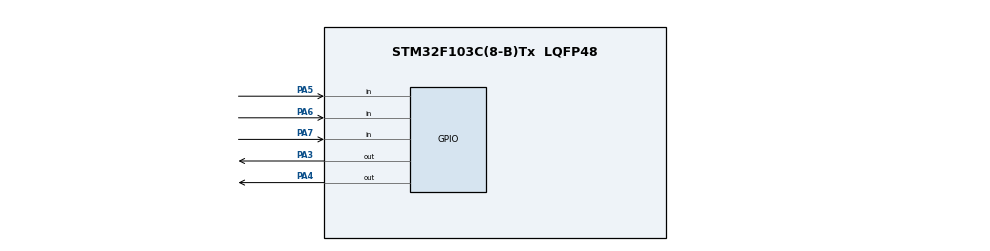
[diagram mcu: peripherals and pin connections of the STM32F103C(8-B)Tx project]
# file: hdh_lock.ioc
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FREERTOS.Tasks01=Task1,0,128,Task1_function,Default,NULL,Dynamic,NULL,NULL;Task2,0,128,Task2_function,Default,NULL,Dynamic,NULL,NULL;Task3,0,128,Task3_function,Default,NULL,Dynamic,NULL,NULL
Mcu.Family=STM32F1
Mcu.Name=STM32F103C(8-B)Tx
Mcu.Package=LQFP48
NVIC.PriorityGroup=NVIC_PRIORITYGROUP_4
NVIC.TIM1_UP_IRQn=true\:15\:0\:false\:false\:true\:false\:false\:true\:true
NVIC.TimeBase=TIM1_UP_IRQn
NVIC.TimeBaseIP=TIM1
PA13.Mode=Serial_Wire
PA13.Signal=SYS_JTMS-SWDIO
PA14.Mode=Serial_Wire
PA14.Signal=SYS_JTCK-SWCLK
PA3.Signal=GPIO_Output
PA4.Signal=GPIO_Output
PA5.GPIO_PuPd=GPIO_PULLDOWN
PA5.Signal=GPIO_Input
PA6.GPIO_PuPd=GPIO_PULLDOWN
PA6.Signal=GPIO_Input
PA7.GPIO_PuPd=GPIO_PULLDOWN
PA7.Signal=GPIO_Input
PD0-OSC_IN.Mode=HSE-External-Oscillator
PD0-OSC_IN.Signal=RCC_OSC_IN
PD1-OSC_OUT.Mode=HSE-External-Oscillator
PD1-OSC_OUT.Signal=RCC_OSC_OUT
ProjectManager.HeapSize=0x200
ProjectManager.StackSize=0x400
ProjectManager.TargetToolchain=MDK-ARM V5
RCC.APB1Freq_Value=8000000
RCC.APB2Freq_Value=8000000
VP_FREERTOS_VS_CMSIS_V1.Mode=CMSIS_V1
VP_SYS_VS_tim1.Mode=TIM1
board=custom

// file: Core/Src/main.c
/* USER CODE BEGIN Header */
/**
  ******************************************************************************
  * @file           : main.c
  * @brief          : Main program body
  ******************************************************************************
  * @attention
  *
  * Copyright (c) 2022 STMicroelectronics.
  * All rights reserved.
  *
  * This software is licensed under terms that can be found in the LICENSE file
  * in the root directory of this software component.
  * If no LICENSE file comes with this software, it is provided AS-IS.
  *
  ******************************************************************************
  */
/* USER CODE END Header */
#include "main.h"
#include "cmsis_os.h"

osThreadId Task1Handle;
osThreadId Task2Handle;
osThreadId Task3Handle;

void SystemClock_Config(void);
static void MX_GPIO_Init(void);
void Task1_function(void const * argument);
void Task2_function(void const * argument);
void Task3_function(void const * argument);

	char lock;

int main(void)
{

  /* MCU Configuration--------------------------------------------------------*/

  /* Reset of all peripherals, Initializes the Flash interface and the Systick. */
  HAL_Init();

  /* Configure the system clock */
  SystemClock_Config();

  /* Initialize all configured peripherals */
  MX_GPIO_Init();

  /* Create the thread(s) */
  /* definition and creation of Task1 */
  osThreadDef(Task1, Task1_function, osPriorityNormal, 0, 128);
  Task1Handle = osThreadCreate(osThread(Task1), NULL);

  /* definition and creation of Task2 */
  osThreadDef(Task2, Task2_function, osPriorityNormal, 0, 128);
  Task2Handle = osThreadCreate(osThread(Task2), NULL);

  /* definition and creation of Task3 */
  osThreadDef(Task3, Task3_function, osPriorityNormal, 0, 128);
  Task3Handle = osThreadCreate(osThread(Task3), NULL);

  /* Start scheduler */
  osKernelStart();

  /* We should never get here as control is now taken by the scheduler */
  /* Infinite loop */
  while (1)
  {

  }
}

void SystemClock_Config(void)
{
  RCC_OscInitTypeDef RCC_OscInitStruct = {0};
  RCC_ClkInitTypeDef RCC_ClkInitStruct = {0};

  /** Initializes the RCC Oscillators according to the specified parameters
  * in the RCC_OscInitTypeDef structure.
  */
  RCC_OscInitStruct.OscillatorType = RCC_OSCILLATORTYPE_HSI;
  RCC_OscInitStruct.HSIState = RCC_HSI_ON;
  RCC_OscInitStruct.HSICalibrationValue = RCC_HSICALIBRATION_DEFAULT;
  RCC_OscInitStruct.PLL.PLLState = RCC_PLL_NONE;
  if (HAL_RCC_OscConfig(&RCC_OscInitStruct) != HAL_OK)
  {
    Error_Handler();
  }

  /** Initializes the CPU, AHB and APB buses clocks
  */
  RCC_ClkInitStruct.ClockType = RCC_CLOCKTYPE_HCLK|RCC_CLOCKTYPE_SYSCLK
                              |RCC_CLOCKTYPE_PCLK1|RCC_CLOCKTYPE_PCLK2;
  RCC_ClkInitStruct.SYSCLKSource = RCC_SYSCLKSOURCE_HSI;
  RCC_ClkInitStruct.AHBCLKDivider = RCC_SYSCLK_DIV1;
  RCC_ClkInitStruct.APB1CLKDivider = RCC_HCLK_DIV1;
  RCC_ClkInitStruct.APB2CLKDivider = RCC_HCLK_DIV1;

  if (HAL_RCC_ClockConfig(&RCC_ClkInitStruct, FLASH_LATENCY_0) != HAL_OK)
  {
    Error_Handler();
  }
}

static void MX_GPIO_Init(void)
{
  GPIO_InitTypeDef GPIO_InitStruct = {0};

  /* GPIO Ports Clock Enable */
  __HAL_RCC_GPIOD_CLK_ENABLE();
  __HAL_RCC_GPIOA_CLK_ENABLE();

  /*Configure GPIO pin Output Level */
  HAL_GPIO_WritePin(GPIOA, GPIO_PIN_3|GPIO_PIN_4, GPIO_PIN_RESET);

  /*Configure GPIO pins : PA3 PA4 */
  GPIO_InitStruct.Pin = GPIO_PIN_3|GPIO_PIN_4;
  GPIO_InitStruct.Mode = GPIO_MODE_OUTPUT_PP;
  GPIO_InitStruct.Pull = GPIO_NOPULL;
  GPIO_InitStruct.Speed = GPIO_SPEED_FREQ_LOW;
  HAL_GPIO_Init(GPIOA, &GPIO_InitStruct);

  /*Configure GPIO pins : PA5 PA6 PA7 */
  GPIO_InitStruct.Pin = GPIO_PIN_5|GPIO_PIN_6|GPIO_PIN_7;
  GPIO_InitStruct.Mode = GPIO_MODE_INPUT;
  GPIO_InitStruct.Pull = GPIO_PULLDOWN;
  HAL_GPIO_Init(GPIOA, &GPIO_InitStruct);

}

void Task1_function(void const * argument)
{
  /* USER CODE BEGIN 5 */
  /* Infinite loop */
  for(;;)
  {
		if (lock==0)
			HAL_GPIO_TogglePin(GPIOA, GPIO_PIN_3);
		osDelay(100);
  }
  /* USER CODE END 5 */
}

void Task2_function(void const * argument)
{
  /* USER CODE BEGIN Task2_function */
  /* Infinite loop */
  for(;;)
  {
		if(HAL_GPIO_ReadPin(GPIOA, GPIO_PIN_5)==1)
		{
			HAL_GPIO_WritePin(GPIOA, GPIO_PIN_4,1);
			while(HAL_GPIO_ReadPin(GPIOA, GPIO_PIN_5)==1) {};// chong doi
		}
		if(HAL_GPIO_ReadPin(GPIOA, GPIO_PIN_6)==1)
		{
			HAL_GPIO_WritePin(GPIOA, GPIO_PIN_4,0);
			while(HAL_GPIO_ReadPin(GPIOA, GPIO_PIN_6)==1) {};// chong doi
		}
    osDelay(100);
  }
  /* USER CODE END Task2_function */
}

void Task3_function(void const * argument)
{
  /* USER CODE BEGIN Task3_function */
  /* Infinite loop */
  for(;;)
  {
    if (HAL_GPIO_ReadPin(GPIOA,GPIO_PIN_7)==1)
		{
			lock =!lock;
			while (HAL_GPIO_ReadPin(GPIOA,GPIO_PIN_7)==1) {};
		}
		osDelay(100);
  }
  /* USER CODE END Task3_function */
}

void HAL_TIM_PeriodElapsedCallback(TIM_HandleTypeDef *htim)
{
  if (htim->Instance == TIM1) {
    HAL_IncTick();
  }
}

void Error_Handler(void)
{
  __disable_irq();
  while (1)
  {
  }
}
